# nrf9160 register map
Vendor: Nordic Semiconductor; Series: nrf91; File version: 1
CPU: CM33 r0p4, little endian, MPU, FPU, 3 interrupt priority bits, 69 interrupts
Registers are 32-bit, read-write, reset 0x0 unless marked. A register's access mark holds for its fields unless they carry their own. Offsets are from the block's base; [hi:lo] are bit positions.

## CC_AHB_S — CRYPTOCELL AHB interface
Base 0x50841000; alternate view of CC_AES_S
0xB00 AHBM_SINGLES — This register forces the AHB transactions from CRYPTOCELL master to be always singles.
  [0] AHB_SINGLES — Force AHB singles
0xB04 AHBM_HPROT — This register holds the AHB HPROT value
  [3:0] AHB_HPROT — The AHB HPROT value
0xB08 AHBM_HMASTLOCK — This register holds AHB HMASTLOCK value
  [0] AHB_HMASTLOCK — The AHB HMASTLOCK value.
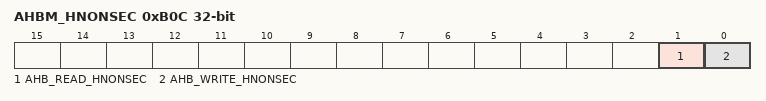
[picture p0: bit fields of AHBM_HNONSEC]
0xB0C AHBM_HNONSEC — This register holds AHB HNONSEC value
  [1] AHB_READ_HNONSEC — The AHB HNONSEC value for read transaction.
  [0] AHB_WRITE_HNONSEC — The AHB HNONSEC value for write transaction.

## CC_CTL_S — CRYPTOCELL CTL interface
Base 0x50841000; alternate view of CC_AES_S
0x900 CRYPTO_CTL wo — Defines the cryptographic flow.
  [4:0] MODE — Configure the cryptographic engine mode.
    0=Bypass cryptographic engine; 1=AESActive (Use AES engine); 2=AESToHashActive (Pipe AES engine output to HASH engine input); 3=AESAndHashActive (Process input using both AES and HASH engine in parallell); 7=HashActive (Use HASH engine); 9=AESMACAndBypassActive (Calculate AES MAC and bypass); 10=AESToHashAndDOUTActive (Pipe AES engine output to HASH engine input. The resulting digest output is piped to DOUT buffer.); 16=ChaChaActive (Use CHACHA engine)
0x910 CRYPTO_BUSY ro — Status register for cryptographic cores engine activity.
  [0] STATUS — Cryptographic core engines status.
    0=Idle (Cryptographic core engines are idle); 1=Busy (Cryptographic core engines are busy)
0x91C HASH_BUSY ro — Status register for HASH engine activity.
  [0] STATUS — Hash engine status.
    0=Idle (HASH engine is idle); 1=Busy (HASH engine is busy)
0x930 CONTEXT_ID — A general-purpose read/write register.
  [7:0] CONTEXT_ID

## CC_DIN_S — CRYPTOCELL Data IN interface
Base 0x50841000; alternate view of CC_AES_S
0xC00 DIN_BUFFER wo — Used by CPU to write data directly to the DIN buffer, which is then sent to the cryptographic engines for processing.
  [31:0] DATA — This register is mapped into 8 addresses in order to enable a CPU burst.
0xC20 DIN_DMA_MEM_BUSY ro — Status register for DIN DMA engine activity when accessing memory.
  [0] STATUS — DIN memory DMA engine status.
    0=Idle (DIN memory DMA engine is idle); 1=Busy (DIN memory DMA engine is busy)
0xC28 SRC_MEM_ADDR wo — Data source address in memory.
  [31:0] ADDR — Source address in memory.
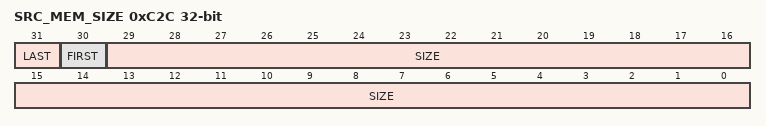
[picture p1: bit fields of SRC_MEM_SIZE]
0xC2C SRC_MEM_SIZE wo — The number of bytes to be read from memory. Writing to this register triggers the DMA operation.
  [31] LAST — This field is reserved
  [30] FIRST — This field is reserved
  [29:0] SIZE — Total number of bytes to read from memory.
0xC30 SRC_SRAM_ADDR — Data source address in RNG SRAM.
  [31:0] ADDR — Source address in RNG SRAM.
0xC34 SRC_SRAM_SIZE wo — The number of bytes to be read from RNG SRAM. Writing to this register triggers the DMA operation.
  [31:0] SIZE — Total number of bytes to read from RNG SRAM.
0xC38 DIN_DMA_SRAM_BUSY ro — Status register for DIN DMA engine activity when accessing RNG SRAM.
  [0] STATUS — DIN RNG SRAM DMA engine status.
    0=Idle (DIN RNG SRAM DMA engine is idle); 1=Busy (DIN RNG SRAM DMA engine is busy)
0xC3C DIN_DMA_SRAM_ENDIANNESS — Configure the endianness of DIN DMA transactions towards RNG SRAM.
  [0] ENDIAN — Endianness of DIN DMA transactions towards RNG SRAM. The default value is little-endian.
    0=LittleEndian (Use little-endian format for RNG SRAM DMA transactions); 1=BigEndian (Use big-endian format for RNG SRAM DMA transactions)
0xC44 DIN_SW_RESET wo — Reset the DIN DMA engine.
  [0] RESET — Writing any value to this address resets the DIN DMA engine. The reset takes 4 CPU clock cycles to complete.
    1=Enable (Reset DIN DMA engine.)
0xC48 DIN_CPU_DATA wo — Specifies the number of bytes the CPU will write to the DIN_BUFFER, ensuring the cryptographic engine processes the correct amount of data.
  [15:0] SIZE — When using CPU direct write to the DIN_BUFFER, the size of input data in bytes should be written to this register.
0xC4C DIN_WRITE_ALIGN wo — Indicates that the next CPU write to the DIN_BUFFER is the last in the sequence. This is needed only when the data size is NOT modulo 4 (e.g. HASH padding).
  [0] LAST — Next CPU write to the DIN_BUFFER is the last word.
    1=Confirm (The next CPU write is the last in the sequence.)
0xC50 DIN_FIFO_EMPTY ro reset 0x1 — Register indicating if DIN FIFO is empty and if more data can be accepted.
  [0] STATUS — DIN FIFO status
    0=NotEmpty (DIN FIFO is not empty); 1=Empty (DIN FIFO is empty, and more data can be accepted)
0xC58 DIN_FIFO_RESET wo — Reset the DIN FIFO, effectively clearing the FIFO for new data.
  [0] RESET — Writing any value to this address resets the DIN FIFO.
    1=Enable (Reset DIN FIFO.)
